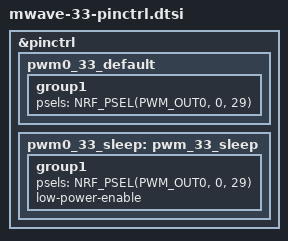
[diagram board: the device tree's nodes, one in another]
/*
 * Copyright (c) 2024 The ZMK Contributors
 * SPDX-License-Identifier: MIT
 */

 &pinctrl {
    pwm0_33_default: pwm0_33_default {
        group1 {
            psels = <NRF_PSEL(PWM_OUT0, 0, 29)>;
        };
    };
    pwm0_33_sleep: pwm_33_sleep {
        group1 {
            psels = <NRF_PSEL(PWM_OUT0, 0, 29)>;
            low-power-enable;
        };
    };
};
